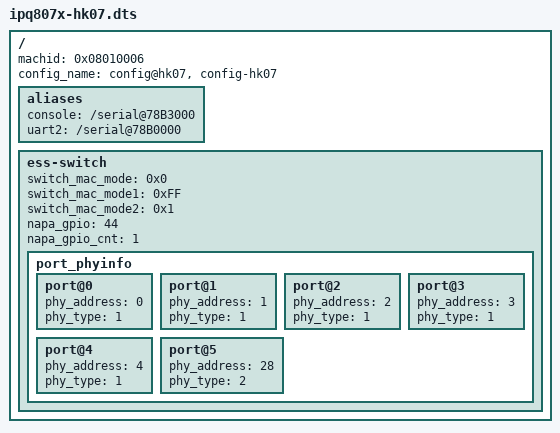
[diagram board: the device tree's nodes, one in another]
/*
 * Copyright (c) 2016 - 2018, The Linux Foundation. All rights reserved.
 *
 * This program is free software; you can redistribute it and/or modify
 * it under the terms of the GNU General Public License version 2 and
 * only version 2 as published by the Free Software Foundation.
 *
 * This program is distributed in the hope that it will be useful,
 * but WITHOUT ANY WARRANTY; without even the implied warranty of
 * MERCHANTABILITY or FITNESS FOR A PARTICULAR PURPOSE.  See the
 * GNU General Public License for more details.
 */

/dts-v1/;
#include "ipq807x-soc.dtsi"
#include <dt-bindings/qcom/gpio-ipq807x.h>
/ {
	machid = <0x08010006>;
	config_name = "config@hk07", "config-hk07";

	aliases {
		console = "/serial@78B3000";
		uart2 = "/serial@78B0000";
	};
	ess-switch {
		switch_mac_mode = <0x0>;
		switch_mac_mode1 = <0xFF>;
		switch_mac_mode2 = <0x1>;
		napa_gpio = <44>;
		napa_gpio_cnt = <1>;
		port_phyinfo {
			port@0 {
				phy_address = <0>;
				phy_type = <1>;
			};
			port@1 {
				phy_address = <1>;
				phy_type = <1>;
			};
			port@2 {
				phy_address = <2>;
				phy_type = <1>;
			};
			port@3 {
				phy_address = <3>;
				phy_type = <1>;
			};
			port@4 {
				phy_address = <4>;
				phy_type = <1>;
			};
			port@5 {
				phy_address = <28>;
				phy_type = <2>;
			};
		};
	};
};

